# dm646x_cslr_edma3cc register map
Vendor: Texas Instruments
Peripheral module from a debugger description file.
Registers are 32-bit, write-only, reset 0x0 unless marked. A register's access mark holds for its fields unless they carry their own. Offsets are as the file gives them; lines under a group give offsets from that group; [hi:lo] are bit positions; {n}, {i} and the like mark numbered series; 'fields as' and 'values as' point back to an identical list; <NAME> marks a mode.

## EDMA3CC — Enhanced DMA Channel Controller Module.
0x00 PID ro reset 0x40011B00 — Peripheral Revision
  [31:0] PID — Peripheral identifier uniquely identifies the EDMA3CC and the specific revision of the EDMA3CC
{0x0+8i} DRA[{i}] (i=0..7) group — DMA Region Access
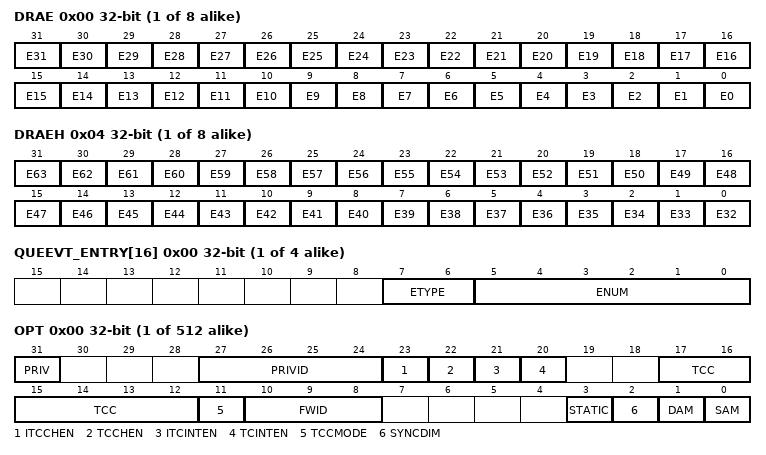
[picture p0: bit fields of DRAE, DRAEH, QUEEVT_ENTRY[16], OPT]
  0x00 DRAE rw — DMA Region Access Enable
    [n] E{n} (n=0..31) — DMA region access enable for bit {n}/channel {n} in region m (m = 0 to 7)
  0x04 DRAEH rw — DMA Region Access Enable High
    [n-32] E{n} (n=32..63) — DMA region access enable for bit {n}/channel {n} in region m (m = 0 to 7)
{0x0+0x40*i} QUEEVTENTRY[{i}] (i=0..3) group — Queue Event Entry matrix
  0x00 QUEEVT_ENTRY[16] ro — Event Entry{EVT_ENTRY}
    [7:6] ETYPE — Event Type
      0=EVENT (Event Triggered via ER); 1=MANUAL (Manual Triggered via ESR); 2=CHAIN (Chain Triggered via CER); 3=AUTO (Auto Triggered via QER)
    [5:0] ENUM — Event Number (0-63)/(0-3)
{0x0+0x20*i} PARAMSET[{i}] (i=0..511) group
  0x00 OPT access not given — Option
    [31] PRIV ro — Privilege level (supervisor versus user) for the host/CPU/DMA that programmed this PaRAM set
      0=USER (User level privilege); 1=SUPERVISOR (Supervisor level privilege)
    [27:24] PRIVID ro — Privilege ID for external host/cpu/dma
    [23] ITCCHEN rw — Intermediate transfer completion chaining enable
      0=DISABLE (ITCC Disabled); 1=ENABLE (ITCC Enabled)
    [22] TCCHEN rw — Transfer completion chaining enable
      0=DISABLE (TCC Disabled); 1=ENABLE (TCC Enabled)
    [21] ITCINTEN rw — Intermediate transfer completion interrupt enable
      0=DISABLE; 1=ENABLE
    [20] TCINTEN rw — Transfer completion interrupt enable
      0=DISABLE; 1=ENABLE
    [17:12] TCC rw — Transfer completion code
    [11] TCCMODE rw — Transfer completion mode
      0=NORMAL; 1=EARLY
    [10:8] FWID rw — Fifo Width
      0=8; 1=16; 2=32; 3=64; 4=128; 5=256
    [3] STATIC rw — Static set
      0=NORMAL; 1=STATIC
    [2] SYNCDIM rw — Transfer Synchronization Dimension
      0=ASYNC; 1=ABSYNC
    [1] DAM rw — Destination address mode
      0=INCR; 1=FIFO
    [0] SAM rw — Source address mode
      0=INCR; 1=FIFO
  0x04 SRC rw — Source Address
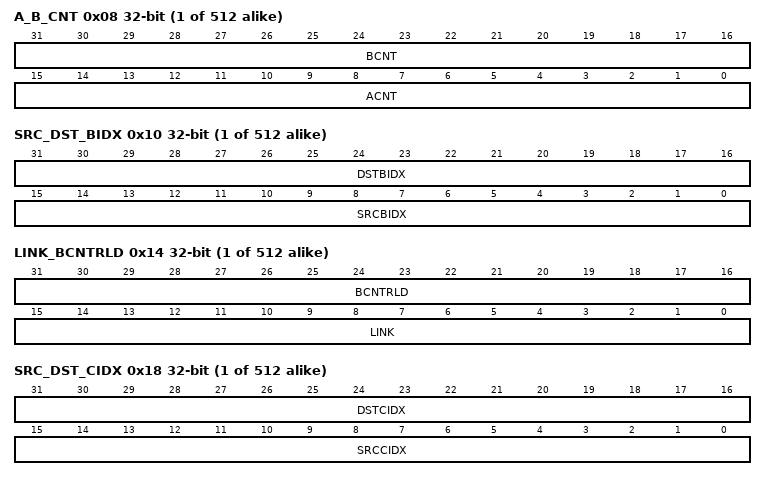
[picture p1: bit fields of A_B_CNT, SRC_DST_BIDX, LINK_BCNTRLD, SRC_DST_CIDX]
  0x08 A_B_CNT rw — A Count
    [31:16] BCNT — B Count
    [15:0] ACNT — A Count
  0x0C DST rw — Destination Address
  0x10 SRC_DST_BIDX rw — SRC B Index, DST B Index
    [31:16] DSTBIDX — Destination B Index
    [15:0] SRCBIDX — Source B Index
  0x14 LINK_BCNTRLD rw — Link Address
    [31:16] BCNTRLD — B Count Reload
    [15:0] LINK — Link Address
  0x18 SRC_DST_CIDX rw — Source C Index
    [31:16] DSTCIDX — Destination C Index
    [15:0] SRCCIDX — Source C Index
  0x1C CCNT access not given — C Count
    [15:0] CCNT rw — C Counter
{0x0+0x200*i} SHADOW[{i}] (i=0..7) group — SHADOWREG
  0x00 ER ro — Event Register
    [31:0] REG
  0x04 ERH ro — Event Register High
    [31:0] REG
  0x08 ECR — Event Clear Register
    [31:0] REG
  0x0C ECRH — Event Clear Register High
    [31:0] REG
  0x10 ESR — Event Set Register
    [31:0] REG
  0x14 ESRH — Event Set Register High
    [31:0] REG
  0x18 CER ro — Chained Event Register
    [31:0] REG
  0x1C CERH ro — Chained Event Register High
    [31:0] REG
  0x20 EER ro — Event Enable Register
    [31:0] REG
  0x24 EERH ro — Event Enable Register High
    [31:0] REG
  0x28 EECR — Event Enable Clear Register
    [31:0] REG
  0x2C EECRH — Event Enable Clear Register High
    [31:0] REG
  0x30 EESR — Event Enable Set Register
    [31:0] REG
  0x34 EESRH — Event Enable Set Register High
    [31:0] REG
  0x38 SER ro — Secondary Event Register
    [31:0] REG
  0x3C SERH ro — Secondary Event Register High
    [31:0] REG
  0x40 SECR — Secondary Event Clear Register
    [31:0] REG
  0x44 SECRH — Secondary Event Clear Register High
    [31:0] REG
  0x50 IER ro — Interrupt Enable Register
    [31:0] REG
  0x54 IERH ro — Interrupt Enable Register High
    [31:0] REG
  0x58 IECR — Interrupt Enable Clear Register
    [31:0] REG
  0x5C IECRH — Interrupt Enable Clear Register High
    [31:0] REG
  0x60 IESR — Interrupt Enable Set Register
    [31:0] REG
  0x64 IESRH — Interrupt Enable Set Register High
    [31:0] REG
  0x68 IPR ro — Interrupt Pending Register
    [31:0] REG
  0x6C IPRH ro — Interrupt Pending Register High
    [31:0] REG
  0x70 ICR — Interrupt Clear Register
    [31:0] REG
  0x74 ICRH — Interrupt Clear Register High
    [31:0] REG
  0x78 IEVAL access not given — Interrupt Eval Register
    [0] EVAL wo — Interrupt Evaluate
      1=EVAL (Causes Region interrupt output to be pulsed is any enabled IERn and IPRn pending also masked by DRAEn)
  0x80 QER access not given — QDMA Event Register
    [7:0] REG ro — Control for each of the eight QDMA channels.
  0x84 QEER access not given — QDMA Event Enable Register
    [7:0] REG ro — Control for each of the eight QDMA channels.
  0x88 QEECR access not given — QDMA Event Enable Clear Register
    [7:0] REG ro — Control for each of the eight QDMA channels.
  0x8C QEESR access not given — QDMA Event Enable Set Register
    [31:0] REG wo
  0x90 QSER access not given — QDMA Secondary Event Register
    [31:0] REG ro
  0x94 QSECR access not given — QDMA Secondary Event Clear Register
    [31:0] REG wo
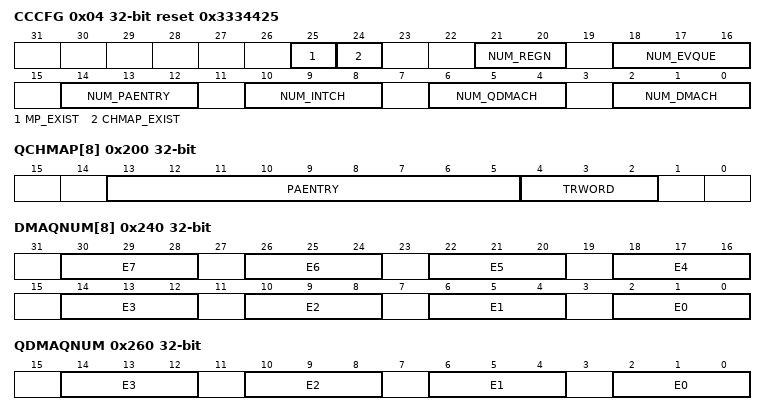
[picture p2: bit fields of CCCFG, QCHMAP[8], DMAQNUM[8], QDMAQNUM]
0x04 CCCFG access not given reset 0x3334425 — CC Configuration
  [25] MP_EXIST ro — Memory Protection Existence
    0=EXCLUDED (Memory protection logic not included.)
  [24] CHMAP_EXIST ro — Channel Mapping Existence
    1=INCLUDED (Channel mapping logic included)
  [21:20] NUM_REGN ro — Number of MP and Shadow regions
    3=8 Regions
  [18:16] NUM_EVQUE ro — Number of Queues/Number of TCs
    3=4 TC/Event Queue
  [14:12] NUM_PAENTRY ro — Number of PaRAM entries
    5=512 Entries
  [10:8] NUM_INTCH ro — Number of Interrupt Channels
    4=64 Interrupt Channels
  [6:4] NUM_QDMACH ro — Number of QDMA Channels
    4=8 QDMA Channels
  [2:0] NUM_DMACH ro — Number of DMA Channels
    5=64 DMA Channels
0x100 DCHMAP[64] access not given — DMA Channel Mapping to PaRAM{DCHMAP}
  [13:5] PAENTRY rw — Points to the PaRAM Entry number for the DMA Channel N
0x200 QCHMAP[8] access not given — QDMA Channel Mapping to PaRAM{QCHMAP}
  [13:5] PAENTRY rw — Points to the PaRAM Entry number for the QDMA Channel N
  [4:2] TRWORD rw — Points to the specific trigger word of the PaRAM set defined by PAENTRY. A write to the trigger word results in a QDMA event being recognized
0x240 DMAQNUM[8] access not given — DMA Queue Number{DMAQNUM}
  [4n+2:4n] E{n} rw (n=0..7) — Event number = (ArrayIndex * 8) + {n}
0x260 QDMAQNUM access not given — QDMA Queue Number
  [4n+2:4n] E{n} rw (n=0..3) — Event number {n}
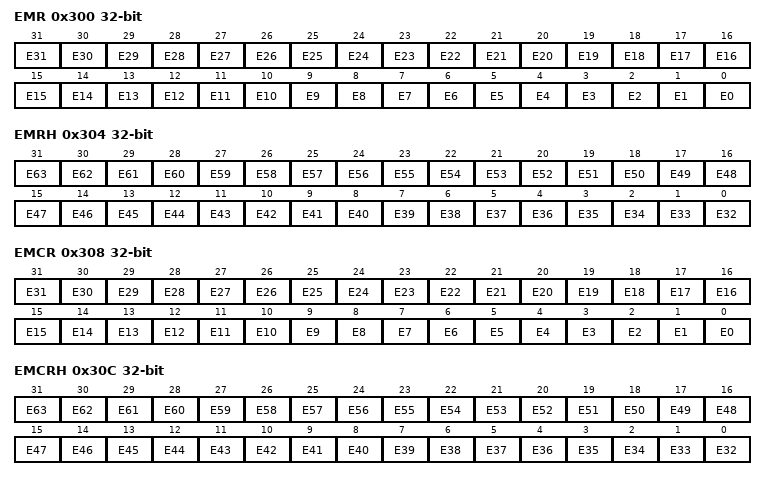
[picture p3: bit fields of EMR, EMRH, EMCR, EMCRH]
0x300 EMR ro — Event Miss Register
  [n] E{n} (n=0..31) — Event missed number {n}
0x304 EMRH ro — Event Miss Register High
  [n-32] E{n} (n=32..63) — Event missed number {n}
0x308 EMCR — Event Miss Clear Register
  [all] fields
    1=CLEAR
  [n] E{n} (n=0..31) — Event missed {n} clear
0x30C EMCRH — Event Miss Clear Register High
  [all] fields
    1=CLEAR
  [n-32] E{n} (n=32..63) — Event missed {n} clear
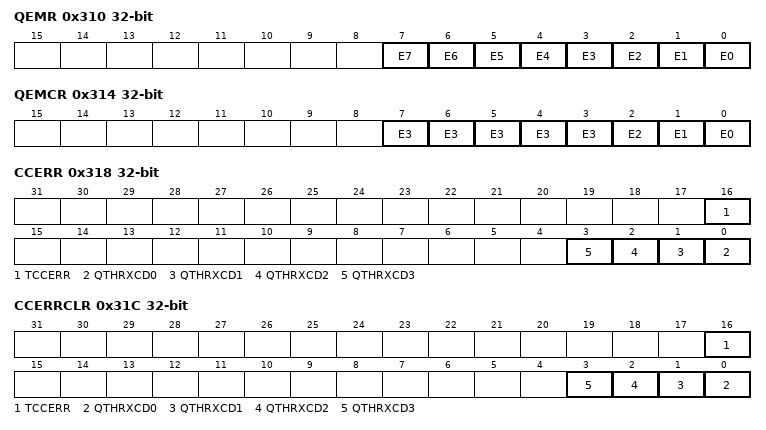
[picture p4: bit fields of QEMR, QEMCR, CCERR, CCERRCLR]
0x310 QEMR access not given — QDMA Event Miss Register
  [n] E{n} ro (n=0..7) — Event miss event {n}
0x314 QEMCR access not given — QDMA Event Miss Register
  [all] fields
    1=CLEAR
  [7] E3 wo — QDMA miss event 7 clear
  [6] E3 wo — QDMA miss event 6 clear
  [5] E3 wo — QDMA miss event 5 clear
  [4] E3 wo — QDMA miss event 4 clear
  [3] E3 wo — QDMA miss event 3 clear
  [2] E2 wo — QDMA miss event 2 clear
  [1] E1 wo — QDMA miss event 1 clear
  [0] E0 wo — QDMA miss event 0 clear
0x318 CCERR access not given — CC Error Register
  [16] TCCERR ro — Transfer completion code error
  [n] QTHRXCD{n} ro (n=0..3) — Queue Threshold Error for Queue {n}
0x31C CCERRCLR access not given — CC Error Clear Register
  [all] fields
    1=CLEAR
  [16] TCCERR wo — Transfer completion code error clear
  [n] QTHRXCD{n} wo (n=0..3) — Queue Threshold Error Clear for Queue {n}
0x320 EEVAL access not given — Error Evaluation Register
  [0] EVAL wo — Error interrupt Evaluate
    1=EVAL (Error Interrupt Evaluate)
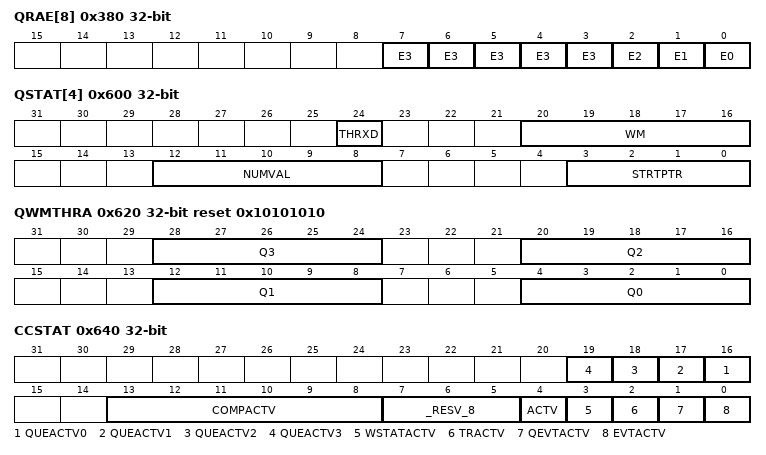
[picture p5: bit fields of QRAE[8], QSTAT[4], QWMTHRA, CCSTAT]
0x380 QRAE[8] access not given — QDMA Region Access Enable{QRAE}
  [7] E3 rw — QDMA region access enable for bit 7/channel 7 in region m (m = 0 to 7)
  [6] E3 rw — QDMA region access enable for bit 6/channel 6 in region m (m = 0 to 7)
  [5] E3 rw — QDMA region access enable for bit 5/channel 5 in region m (m = 0 to 7)
  [4] E3 rw — QDMA region access enable for bit 4/channel 4 in region m (m = 0 to 7)
  [3] E3 rw — QDMA region access enable for bit 3/channel 3 in region m (m = 0 to 7)
  [2] E2 rw — QDMA region access enable for bit 2/channel 2 in region m (m = 0 to 7)
  [1] E1 rw — QDMA region access enable for bit 1/channel 1 in region m (m = 0 to 7)
  [0] E0 rw — QDMA region access enable for bit 0/channel 0 in region m (m = 0 to 7)
0x600 QSTAT[4] access not given — Queue Status{QSTAT}
  [24] THRXD ro — Threshold Exceeded
    0=NOTEXCEED (Not Exceeded); 1=EXCEED (Exceeded)
  [20:16] WM ro — Watermark for Maximum Queue Usage
    0=EMPTY (Empty Queue); 22=FULL (Full Queue)
  [12:8] NUMVAL ro — Number of Valid Entries in Queue
  [3:0] STRTPTR ro — Start Pointer
0x620 QWMTHRA access not given reset 0x10101010 — Queue Watermark Threshold A Register
  [all] fields
    23=DISABLE (Disable threshold errors)
  [8n+4:8n] Q{n} rw (n=0..3) — Queue threshold for queue {n} value
0x640 CCSTAT access not given — Channel Controller Status
  [n+16] QUEACTV{n} ro (n=0..3) — Queue {n} Active
    0=NONE; 1=ACTIVE
  [13:8] COMPACTV ro — Completion Request Active
    0=NONE
  [7:5] _RESV_8 — (access N)
  [4] ACTV ro — Channel Controller Active
    0=IDLE; 1=BUSY
  [3] WSTATACTV ro — Write Status iterface Active
    0=IDLE; 1=BUSY
  [2] TRACTV ro — Transfer Request Active
    0=NONE; 1=ACTIVE
  [1] QEVTACTV ro — QDMA Event Active
    0=NONE; 1=ACTIVE
  [0] EVTACTV ro — DMA Event Active
    0=NONE; 1=ACTIVE
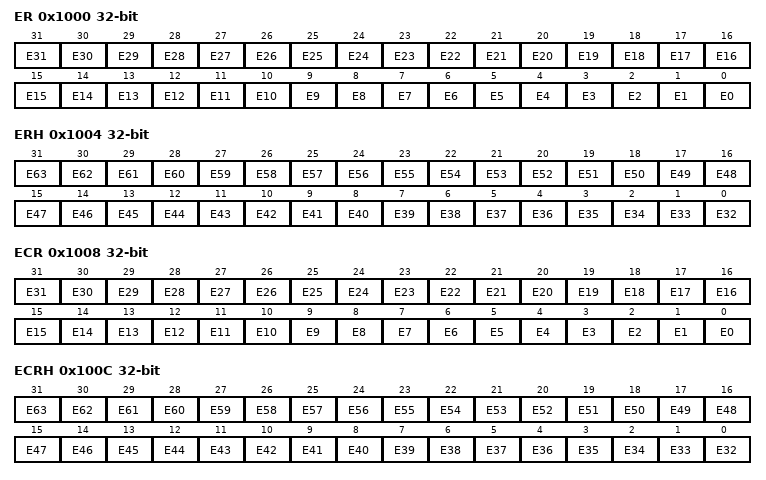
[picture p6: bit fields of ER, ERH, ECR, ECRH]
0x1000 ER ro — Event Register
  [n] E{n} (n=0..31) — Event {n}
0x1004 ERH ro — Event Register High
  [n-32] E{n} (n=32..63) — Event {n}
0x1008 ECR — Event Clear Register
  [all] fields
    1=CLEAR
  [n] E{n} (n=0..31) — Event clear for event {n}
0x100C ECRH — Event Clear Register High
  [all] fields
    1=CLEAR
  [n-32] E{n} (n=32..63) — Event clear for event {n}
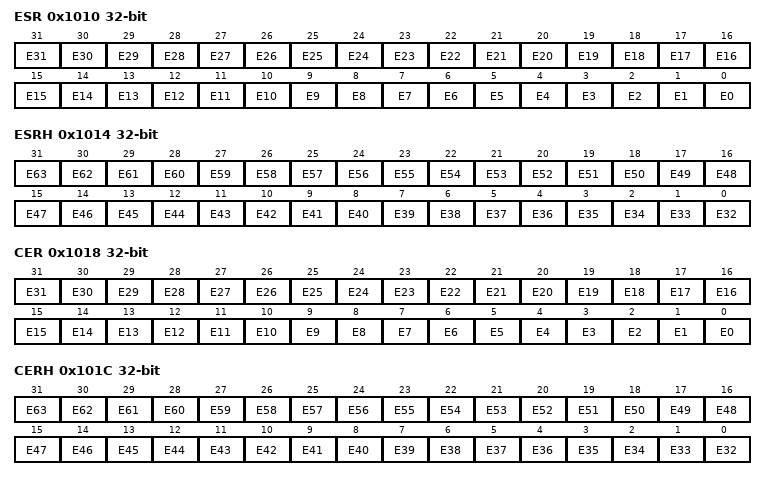
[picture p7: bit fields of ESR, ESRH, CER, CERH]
0x1010 ESR rw — Event Set Register
  [all] fields
    1=SET
  [n] E{n} (n=0..31) — Event set for event {n}
0x1014 ESRH rw — Event Set Register High
  [all] fields
    1=SET
  [n-32] E{n} (n=32..63) — Event set for event {n}
0x1018 CER ro — Chained Event Register
  [n] E{n} (n=0..31) — Chained event for event {n}
0x101C CERH ro — Chained Event Register High
  [n-32] E{n} (n=32..63) — Chained event for event {n}
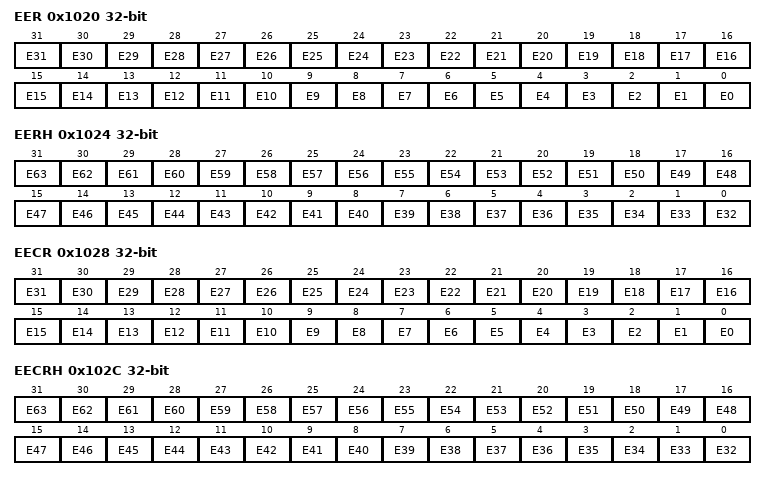
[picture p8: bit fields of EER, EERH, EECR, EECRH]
0x1020 EER ro — Event Enable Register
  [31] E31 — Event enable for events 31
    1=?
  [n] E{n} (n=0..30) — Event enable for events {n}
0x1024 EERH ro — Event Enable Register High
  [n-32] E{n} (n=32..63) — Event enable for events {n}
0x1028 EECR — Event Enable Clear Register
  [all] fields
    1=CLEAR
  [n] E{n} (n=0..31) — Event enable clear for events {n}
0x102C EECRH — Event Enable Clear Register High
  [all] fields
    1=CLEAR
  [n-32] E{n} (n=32..63) — Event enable clear for events {n}
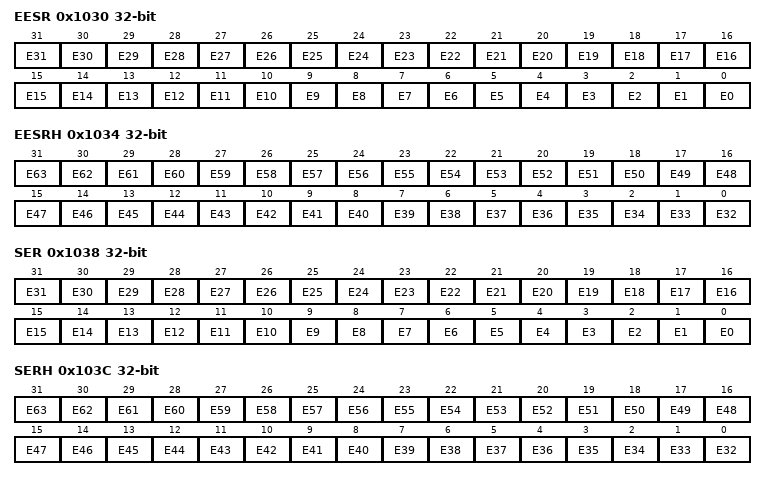
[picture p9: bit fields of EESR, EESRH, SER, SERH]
0x1030 EESR — Event Enable Set Register
  [all] fields
    1=SET
  [n] E{n} (n=0..31) — Event enable set for events {n}
0x1034 EESRH — Event Enable Set Register High
  [all] fields
    1=SET
  [n-32] E{n} (n=32..63) — Event enable set for events {n}
0x1038 SER ro — Secondary Event Register
  [n] E{n} (n=0..31) — Event {n}
0x103C SERH ro — Secondary Event Register High
  [n-32] E{n} (n=32..63) — Event {n}
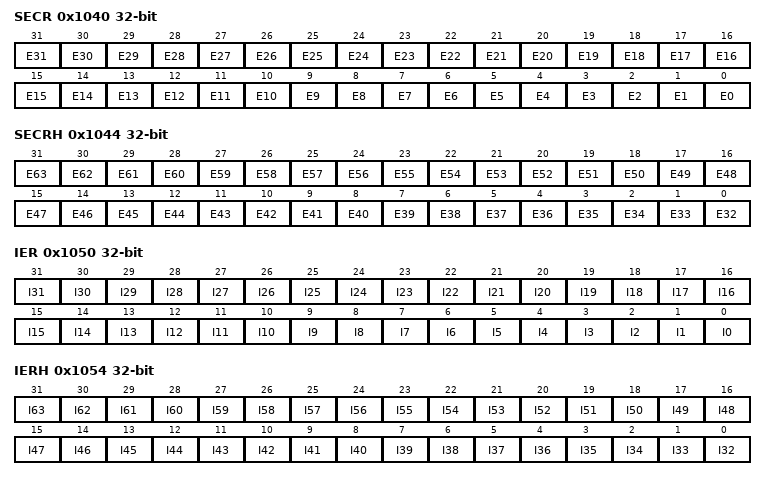
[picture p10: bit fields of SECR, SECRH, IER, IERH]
0x1040 SECR — Secondary Event Clear Register
  [all] fields
    1=CLEAR
  [n] E{n} (n=0..31) — Secondary event clear for event {n}
0x1044 SECRH — Secondary Event Clear Register High
  [all] fields
    1=CLEAR
  [n-32] E{n} (n=32..63) — Secondary event clear for event {n}
0x1050 IER ro — Interrupt Enable Register
  [n] I{n} (n=0..31) — Interrupt enable for channels {n}
0x1054 IERH ro — Interrupt Enable Register High
  [n-32] I{n} (n=32..63) — Interrupt enable for channels {n}
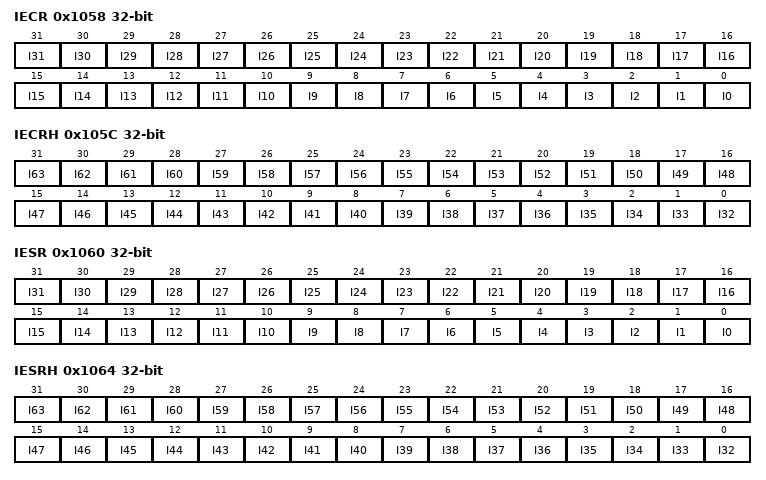
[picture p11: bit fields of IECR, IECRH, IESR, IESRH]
0x1058 IECR — Interrupt Enable Clear Register
  [all] fields
    1=CLEAR
  [n] I{n} (n=0..31) — Interrupt enable clear for channels {n}
0x105C IECRH — Interrupt Enable Clear Register High
  [all] fields
    1=CLEAR
  [n-32] I{n} (n=32..63) — Interrupt enable clear for channels {n}
0x1060 IESR — Interrupt Enable Set Register
  [all] fields
    1=SET
  [n] I{n} (n=0..31) — Interrupt enable set for channels {n}
0x1064 IESRH — Interrupt Enable Set Register High
  [all] fields
    1=SET
  [n-32] I{n} (n=32..63) — Interrupt enable set for channels {n}
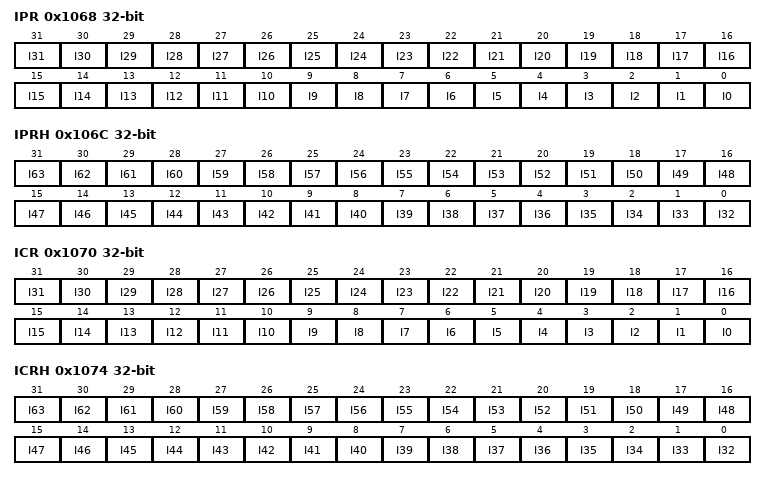
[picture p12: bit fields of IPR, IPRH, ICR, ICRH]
0x1068 IPR ro — Interrupt Pending Register
  [n] I{n} (n=0..31) — Interrupt pending for TCC = {n}
0x106C IPRH ro — Interrupt Pending Register High
  [n-32] I{n} (n=32..63) — Interrupt pending for TCC = {n}
0x1070 ICR — Interrupt Clear Register
  [all] fields
    1=CLEAR
  [n] I{n} (n=0..31) — Interrupt clear for TCC = {n}
0x1074 ICRH — Interrupt Clear Register High
  [all] fields
    1=CLEAR
  [n-32] I{n} (n=32..63) — Interrupt clear for TCC = {n}
0x1078 IEVAL access not given — Interrupt Eval Register
  [0] EVAL wo — Interrupt Evaluate
    1=EVAL (Causes Completion interrupt output to be pulsed is any enabled IERn and IPRn pending)
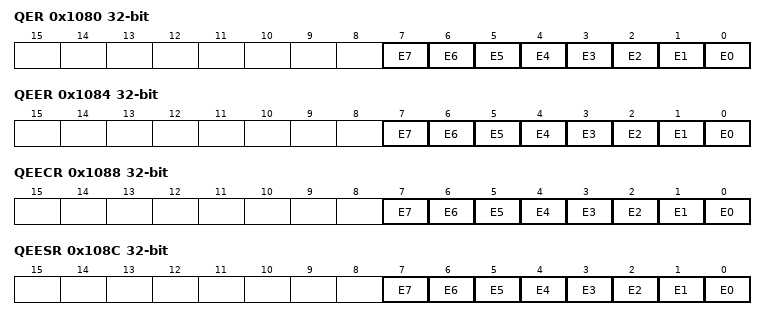
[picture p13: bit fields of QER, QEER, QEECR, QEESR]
0x1080 QER access not given — QDMA Event Register
  [n] E{n} ro (n=0..7) — QDMA event for channels {n}
0x1084 QEER access not given — QDMA Event Enable Register
  [n] E{n} ro (n=0..7) — QDMA event enable for channels {n}
0x1088 QEECR access not given — QDMA Event Enable Clear Register
  [all] fields
    1=CLEAR
  [n] E{n} wo (n=0..7) — QDMA event enable clear for channels {n}
0x108C QEESR access not given — QDMA Event Enable Set Register
  [all] fields
    1=SET
  [n] E{n} wo (n=0..7) — QDMA event enable set for channels {n}
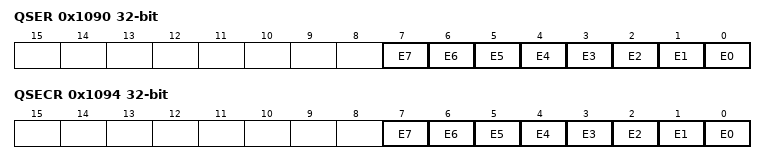
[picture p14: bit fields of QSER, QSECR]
0x1090 QSER access not given — QDMA Secondary Event Register
  [n] E{n} ro (n=0..7) — QDMA secondary event for channels {n}
0x1094 QSECR access not given — QDMA Secondary Event Clear Register
  [all] fields
    1=CLEAR
  [7] E7 wo — QDMA secondary event clear for channels 37
  [n] E{n} wo (n=0..6) — QDMA secondary event clear for channels {n}
